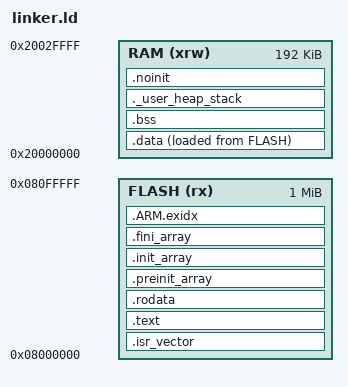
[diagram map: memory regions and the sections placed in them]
/* Linker script for STM32F407xx — 1MB Flash, 192KB SRAM1 at 0x20000000 */

ENTRY(Reset_Handler)

_estack = ORIGIN(RAM) + LENGTH(RAM);

_Min_Heap_Size  = 0x0;
_Min_Stack_Size = 0x800;

MEMORY
{
  FLASH (rx)  : ORIGIN = 0x08000000, LENGTH = 1024K
  RAM   (xrw) : ORIGIN = 0x20000000, LENGTH = 192K
}

SECTIONS
{
  .isr_vector :
  {
    . = ALIGN(4);
    KEEP(*(.isr_vector))
    . = ALIGN(4);
  } >FLASH

  .text :
  {
    . = ALIGN(4);
    *(.text)
    *(.text*)
    *(.glue_7)
    *(.glue_7t)
    *(.eh_frame_hdr)
    *(.eh_frame)
    KEEP (*(.init))
    KEEP (*(.fini))
    . = ALIGN(4);
    _etext = .;
  } >FLASH

  .rodata :
  {
    . = ALIGN(4);
    *(.rodata)
    *(.rodata*)
    *(.gcc_except_table)
    *(.gcc_except_table*)
    . = ALIGN(4);
  } >FLASH

  .preinit_array :
  {
    PROVIDE_HIDDEN (__preinit_array_start = .);
    KEEP (*(.preinit_array*))
    PROVIDE_HIDDEN (__preinit_array_end = .);
  } >FLASH

  .init_array :
  {
    PROVIDE_HIDDEN (__init_array_start = .);
    KEEP (*(SORT(.init_array.*)))
    KEEP (*(.init_array*))
    PROVIDE_HIDDEN (__init_array_end = .);
  } >FLASH

  .fini_array :
  {
    PROVIDE_HIDDEN (__fini_array_start = .);
    KEEP (*(SORT(.fini_array.*)))
    KEEP (*(.fini_array*))
    PROVIDE_HIDDEN (__fini_array_end = .);
  } >FLASH

  .ARM.exidx :
  {
    __exidx_start = .;
    *(.ARM.exidx* .gnu.linkonce.armexidx.*)
    __exidx_end = .;
  } >FLASH

  _sidata = LOADADDR(.data);

  .data :
  {
    . = ALIGN(4);
    _sdata = .;
    *(.data)
    *(.data*)
    . = ALIGN(4);
    _edata = .;
  } >RAM AT> FLASH

  . = ALIGN(4);
  .bss (NOLOAD) :
  {
    _sbss = .;
    __bss_start__ = _sbss;
    *(.bss)
    *(.bss*)
    *(COMMON)
    . = ALIGN(4);
    _ebss = .;
    __bss_end__ = _ebss;
  } >RAM

  ._user_heap_stack :
  {
    . = ALIGN(8);
    PROVIDE ( end = . );
    PROVIDE ( _end = _ebss );
    . = . + _Min_Heap_Size;
    . = . + _Min_Stack_Size;
    . = ALIGN(8);
  } >RAM

  .noinit (NOLOAD) : { *(.noinit*) } >RAM

  .ARM.attributes 0 : { *(.ARM.attributes) }
}

ASSERT(_etext <= ORIGIN(FLASH) + LENGTH(FLASH), "FLASH overflow");
ASSERT(.      <= ORIGIN(RAM)   + LENGTH(RAM),   "RAM overflow (heap/stack)");
